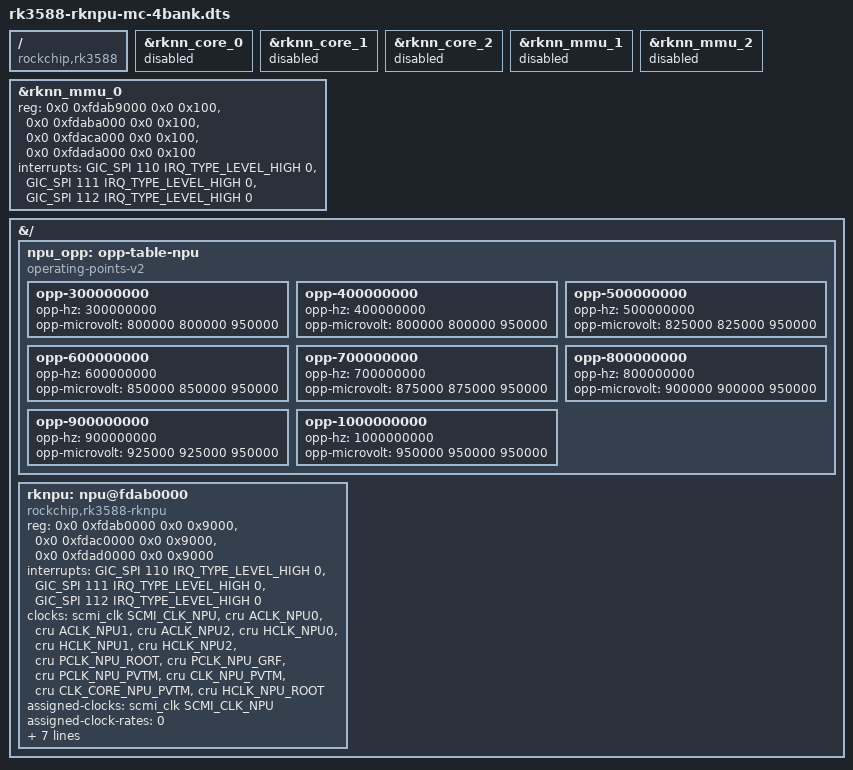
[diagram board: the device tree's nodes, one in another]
// SPDX-License-Identifier: GPL-2.0-only
//
// DT overlay: multi-core RK3588 NPU for the w568w/rknpu-module driver.
//
// Same as rk3588-rknpu-opi5pro.dts (single vendor rknpu node replacing the
// mainline rocket nodes) EXCEPT the IOMMU topology: instead of binding the
// NPU to core0's MMU only, fold ALL FOUR NPU MMU banks into the single
// rknn_mmu_0 iommu node.  Mainline rockchip-iommu programs every "reg" bank
// of one node with the same page table (num_mmu = #reg entries), so all
// three cores translate through one DMA domain — no core is left on a
// bypassed MMU.  The driver detects the 4-bank node at probe and lifts its
// core mask from 0x1 to 0x7 (see rknpu_effective_core_mask in rknpu_drv.c).
//
// Power/clock safety: rknpu_power_on() enables the full clock bulk (incl.
// aclk/hclk for NPU1/NPU2) and syncs all three power domains via the genpd
// virtual devices BEFORE its pm_runtime_get_sync(dev), which is what
// resumes the iommu (device-link supplier) and programs the banks.  So the
// core1/core2 MMU banks are only ever touched powered + clocked.

/dts-v1/;
/plugin/;

#include <dt-bindings/interrupt-controller/arm-gic.h>
#include <dt-bindings/power/rk3588-power.h>
#include <dt-bindings/clock/rockchip,rk3588-cru.h>

/ {
    compatible = "rockchip,rk3588";
};

/* Disable mainline rocket per-core nodes. */
&rknn_core_0 { status = "disabled"; };
&rknn_core_1 { status = "disabled"; };
&rknn_core_2 { status = "disabled"; };

/* Core1/core2 MMU banks are folded into rknn_mmu_0 below; their standalone
 * nodes must be disabled or their probes would claim the same MMIO regions
 * (devm_ioremap_resource -EBUSY) and last-wins of_xlate could rebind the
 * NPU to a bank-1-only IOMMU. */
&rknn_mmu_1 { status = "disabled"; };
&rknn_mmu_2 { status = "disabled"; };

/* One iommu device managing every NPU MMU bank:
 *   fdab9000 / fdaba000 : core0 (two MMU instances, already both in the
 *                         mainline node — proof multi-bank works)
 *   fdaca000            : core1
 *   fdada000            : core2
 * Each bank's fault IRQ is the line it shares with its NPU core (110/111/
 * 112); both rk_iommu and rknpu request them IRQF_SHARED.  The node keeps
 * its own aclk/iface (ACLK_NPU0/HCLK_NPU0) and NPUTOP power domain: banks
 * in NPU1/NPU2 domains are powered/clocked by the rknpu node's held clock
 * bulk + genpd refs whenever they are programmed (see header comment). */
&rknn_mmu_0 {
    reg = <0x0 0xfdab9000 0x0 0x100>,
          <0x0 0xfdaba000 0x0 0x100>,
          <0x0 0xfdaca000 0x0 0x100>,
          <0x0 0xfdada000 0x0 0x100>;
    interrupts = <GIC_SPI 110 IRQ_TYPE_LEVEL_HIGH 0>,
                 <GIC_SPI 111 IRQ_TYPE_LEVEL_HIGH 0>,
                 <GIC_SPI 112 IRQ_TYPE_LEVEL_HIGH 0>;
};

&{/} {
    npu_opp: opp-table-npu {
        compatible = "operating-points-v2";

        /* RK3588 NPU OPPs. Voltages are rounded UP from Rockchip's BSP
         * worst-bin values (300-600 MHz: 675 mV, 700: 700, 800: 750,
         * 900: 800, 1000: 850 mV) for margin, and never below the
         * 800 mV the rail already runs at. vdd_npu_s0's own DT
         * constraints (550-950 mV) cap everything. dev_pm_opp_set_rate
         * raises the regulator to opp-microvolt BEFORE the clock on the
         * way up, so a high clock is never applied at low voltage.
         * Validated on OPi 5 Pro: stable + correct (MobileNet class 156)
         * at every step 300->1000 MHz; 1000 MHz @ 950 mV = 3.7x the
         * 200 MHz throughput, <52 C. */
        opp-300000000 { opp-hz = /bits/ 64 <300000000>; opp-microvolt = <800000 800000 950000>; };
        opp-400000000 { opp-hz = /bits/ 64 <400000000>; opp-microvolt = <800000 800000 950000>; };
        opp-500000000 { opp-hz = /bits/ 64 <500000000>; opp-microvolt = <825000 825000 950000>; };
        opp-600000000 { opp-hz = /bits/ 64 <600000000>; opp-microvolt = <850000 850000 950000>; };
        opp-700000000 { opp-hz = /bits/ 64 <700000000>; opp-microvolt = <875000 875000 950000>; };
        opp-800000000 { opp-hz = /bits/ 64 <800000000>; opp-microvolt = <900000 900000 950000>; };
        opp-900000000 { opp-hz = /bits/ 64 <900000000>; opp-microvolt = <925000 925000 950000>; };
        opp-1000000000 { opp-hz = /bits/ 64 <1000000000>; opp-microvolt = <950000 950000 950000>; };
    };

    rknpu: npu@fdab0000 {
        compatible = "rockchip,rk3588-rknpu", "rockchip,rknpu";
        reg = <0x0 0xfdab0000 0x0 0x9000>,
              <0x0 0xfdac0000 0x0 0x9000>,
              <0x0 0xfdad0000 0x0 0x9000>;
        reg-names = "rknpu_core0", "rknpu_core1", "rknpu_core2";

        interrupts = <GIC_SPI 110 IRQ_TYPE_LEVEL_HIGH 0>,
                     <GIC_SPI 111 IRQ_TYPE_LEVEL_HIGH 0>,
                     <GIC_SPI 112 IRQ_TYPE_LEVEL_HIGH 0>;
        /* Names must match w568w/rknpu-module's of-property lookups
         * (rknpu_drv.c — irqs[].name = "npu0_irq" for multi-core RK3588). */
        interrupt-names = "npu0_irq", "npu1_irq", "npu2_irq";

        /* clk_npu (SCMI) is the NPU compute clock, but each core's
         * register interface is clocked by aclk_npuN/hclk_npuN — and on
         * mainline those clocks belong to the *iommu* nodes, not the NPU
         * node. devm_clk_bulk_get_all() on this node therefore only grabbed
         * clk_npu, leaving the bus clocks to gate whenever the per-core
         * iommu was runtime-suspended. Result: reads of the core register
         * block (e.g. the HW-version register at offset 0) returned 0, so
         * librknnrt misdetected the SoC as RK3566/68 and refused to load any
         * RK3588 model. Listing the six bus clocks here makes power_on's
         * clk_bulk_prepare_enable() hold them on for the whole powered
         * window. clk_npu must stay first — the driver reports FREQ from
         * clks[0].
         *
         * The pclk/pvtm group (PCLK_NPU_ROOT, PCLK_NPU_GRF, the two PVTM
         * clocks, HCLK_NPU_ROOT) is the DVFS-safety set. TF-A's SCMI
         * CLK_NPU set_rate programs the NPU PVTPLL through the NPU GRF
         * over APB; mainline gates pclk_npu_root as unused at boot, and
         * an EL3 APB access through a gated pclk hard-wedges the whole
         * SoC — so ANY NPU frequency change hangs the machine unless
         * these are held (reproduced on OPi 5 Pro: raw set_rate to
         * 300 MHz wedged it; holding these + set_rate is stable to
         * 1000 MHz). Listing them here makes the driver's own
         * clk_bulk_prepare_enable() in power_on hold them whenever the
         * NPU is powered, which is exactly when a set_rate can occur. */
        clocks = <&scmi_clk SCMI_CLK_NPU>,
                 <&cru ACLK_NPU0>, <&cru ACLK_NPU1>, <&cru ACLK_NPU2>,
                 <&cru HCLK_NPU0>, <&cru HCLK_NPU1>, <&cru HCLK_NPU2>,
                 <&cru PCLK_NPU_ROOT>, <&cru PCLK_NPU_GRF>,
                 <&cru PCLK_NPU_PVTM>, <&cru CLK_NPU_PVTM>,
                 <&cru CLK_CORE_NPU_PVTM>, <&cru HCLK_NPU_ROOT>;
        clock-names = "clk_npu", "aclk0", "aclk1", "aclk2",
                      "hclk0", "hclk1", "hclk2",
                      "pclk", "pclk_grf", "pclk_pvtm", "clk_pvtm",
                      "clk_core_pvtm", "hclk_root";

        /* The mainline rknn_core_0 node this overlay merges into carries
         * assigned-clock-rates = <200000000> on SCMI_CLK_NPU, which
         * of_clk_set_defaults applies on EVERY driver bind (of_clk.c
         * only calls clk_set_rate when the rate is non-zero). Once the
         * NPU has been raised above 200 MHz, a module reload would then
         * issue an SCMI CLK_NPU rate change at bind time — before the
         * driver has enabled its clock bulk — with pclk_npu_root/grf
         * potentially gated, and hard-wedge the SoC. Overriding the rate
         * to <0> makes of_clk_set_defaults skip the clock entirely: the
         * NPU keeps whatever rate firmware left (cold boot: the TF-A
         * default) until devfreq raises it through the safe, pclk-held
         * path. */
        assigned-clocks = <&scmi_clk SCMI_CLK_NPU>;
        assigned-clock-rates = <0>;

        power-domains = <&power RK3588_PD_NPUTOP>,
                        <&power RK3588_PD_NPU1>,
                        <&power RK3588_PD_NPU2>;
        /* Driver attaches per-core PM domains via dev_pm_domain_attach_by_name
         * (rknpu_drv.c) using the strings "npu0"/"npu1"/"npu2". */
        power-domain-names = "npu0", "npu1", "npu2";

        /* Single iommu phandle -> the 4-bank rknn_mmu_0 node above.
         * of_xlate binds the NPU to that one iommu device; rk_iommu
         * programs all four banks with the same page table, so cores
         * 0/1/2 all translate through the same DMA domain. */
        iommus = <&rknn_mmu_0>;

        operating-points-v2 = <&npu_opp>;

        /* Same rail under both names. The driver's own vdd lookup and
         * the RKNPU_GET_VOLT ioctl use "rknpu" (vendor-style); the OPP
         * regulator binding in rknpu_devfreq.c probes both "rknpu" and
         * "npu" and uses whichever resolves. Providing both aliases
         * keeps every consumer happy. */
        npu-supply = <&vdd_npu_s0>;
        rknpu-supply = <&vdd_npu_s0>;
        sram-supply = <&vdd_npu_s0>;

        status = "okay";
    };
};
